# soc register map
Vendor: litex
Registers are 32-bit, read-write, reset 0x0 unless marked. A register's access mark holds for its fields unless they carry their own. Offsets are from the block's base; [hi:lo] are bit positions.

## POWER
Base 0xF0014000
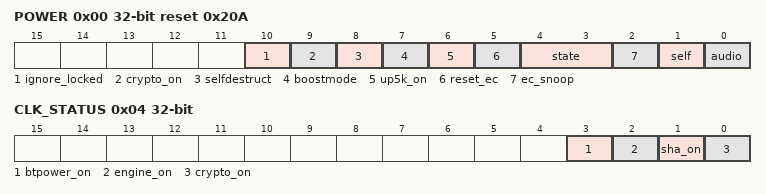
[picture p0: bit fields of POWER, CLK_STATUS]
0x00 POWER reset 0x20A
  [10] ignore_locked — Writing a `1` to this bit causes the reset to ignore the PLL lock status
  [9] crypto_on — Writing a `1` to this bit turns the clock on to the crypto accelerators. Configured to currently override power to `on` at boot to ease system setup.
  [8] selfdestruct — Set this bit to clear BBRAM AES key (if used) and cut power in an annoying-to- reset fashion
  [7] boostmode — Writing a `1` causes the USB port to source 5V. To be active only when playing the host role.
  [6] up5k_on — Writing a `1` pulses the UP5K domain to turn on
  [5] reset_ec — Writing a `1` forces EC into reset. Requires write of `0` to release reset.
  [4:3] state — Current SoC power state. 0x=off or not ready, 10=on and safe to shutdown, 11=on and not safe to shut down, resets to 01 to allow extSRAM access immediately during init
  [2] ec_snoop — Writing `1` allows the insecure EC to snoop a couple keyboard pads for wakeup key sequence recognition
  [1] self — Writing `1` forces self power-on (overrides the EC's ability to power me down)
  [0] audio — Write `1` to power on the audio subsystem
0x04 CLK_STATUS
  [3] btpower_on — Readback of this block's override-on power setting
  [2] engine_on — Readback of Engine25519 block power setting
  [1] sha_on — Readback of SHA block power setting
  [0] crypto_on — The actual crypto clock power on signal, after OR'ing between three separate sources (power, sha512, and engine25519)
0x08 VIBE — Vibration motor configuration register
  [0] vibe — Turn on vibration motor
0x0C EV_STATUS — USB attach event
  [0] usb_attach — Level of the ``usb_attach`` event
0x10 EV_PENDING — USB attach event
  [0] usb_attach
0x14 EV_ENABLE — USB attach event
  [0] usb_attach — Write a ``1`` to enable the ``usb_attach`` Event

## SPINOR
Base 0xF0015000
0x00 CONFIG reset 0xA
  [4:0] dummy — Number of dummy cycles
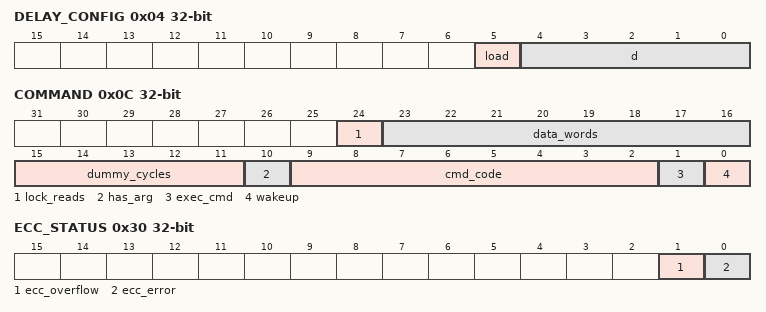
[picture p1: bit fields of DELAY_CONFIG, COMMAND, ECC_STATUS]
0x04 DELAY_CONFIG
  [5] load — Force delay taps to delay_d
  [4:0] d — Delay amount; each increment is 78ps
0x08 DELAY_STATUS
  [4:0] q — Readback of current delay amount, useful if inc/ce is used to set
0x0C COMMAND — Write individual bits to issue special commands to SPI; setting multiple bits at once leads to undefined behavior.
  [24] lock_reads — When set, locks out read operations (recommended when doing programming)
  [23:16] data_words — Number of data words (2x bytes)
  [15:11] dummy_cycles — Number of dummy cycles for manual command; 0 implies a write, >0 implies read
  [10] has_arg — When set, transmits the value of `cmd_arg` as the argument to the command
  [9:2] cmd_code — Manual command code (first 8 bits, e.g. PP4B is 0x12)
  [1] exec_cmd — Writing a `1` executes a manual command
  [0] wakeup — Sequence through init & wakeup routine
0x10 CMD_ARG — Command argument
  [31:0] cmd_arg — Argument to manual command
0x14 CMD_RBK_DATA — Readback data from commands
  [31:0] cmd_rbk_data — Data read back from a cmd_code that has `write_code` set to 0
0x18 STATUS — Interface status
  [0] wip — Operation in progress (write or erease)
0x1C WDATA — Page data to write to FLASH
  [15:0] wdata — 16-bit wide write data presented to FLASH, committed to a 128-entry deep FIFO. Writes to this register are not cached; note that writes to the SPINOR address space are also committed to the FIFO, but this space is cached by the CPU, and therefore not guaranteed to be coherent or in order. The direct wishbone-write address space is provisioned for e.g. USB bus masters that don't have caching.
0x20 EV_STATUS — An ECC event has happened on the current block; triggered by falling edge of ECC_N
  [0] ecc_error — Level of the ``ecc_error`` event
0x24 EV_PENDING — An ECC event has happened on the current block; triggered by falling edge of ECC_N
  [0] ecc_error
0x28 EV_ENABLE — An ECC event has happened on the current block; triggered by falling edge of ECC_N
  [0] ecc_error — Write a ``1`` to enable the ``ecc_error`` Event
0x2C ECC_ADDRESS
  [31:0] ecc_address — Address of the most recent ECC event
0x30 ECC_STATUS
  [1] ecc_overflow — More than one ECS_N event has happened since th last time ecc_address was checked
  [0] ecc_error — Live status of the ECS_N bit (ECC error on current packet when low)
